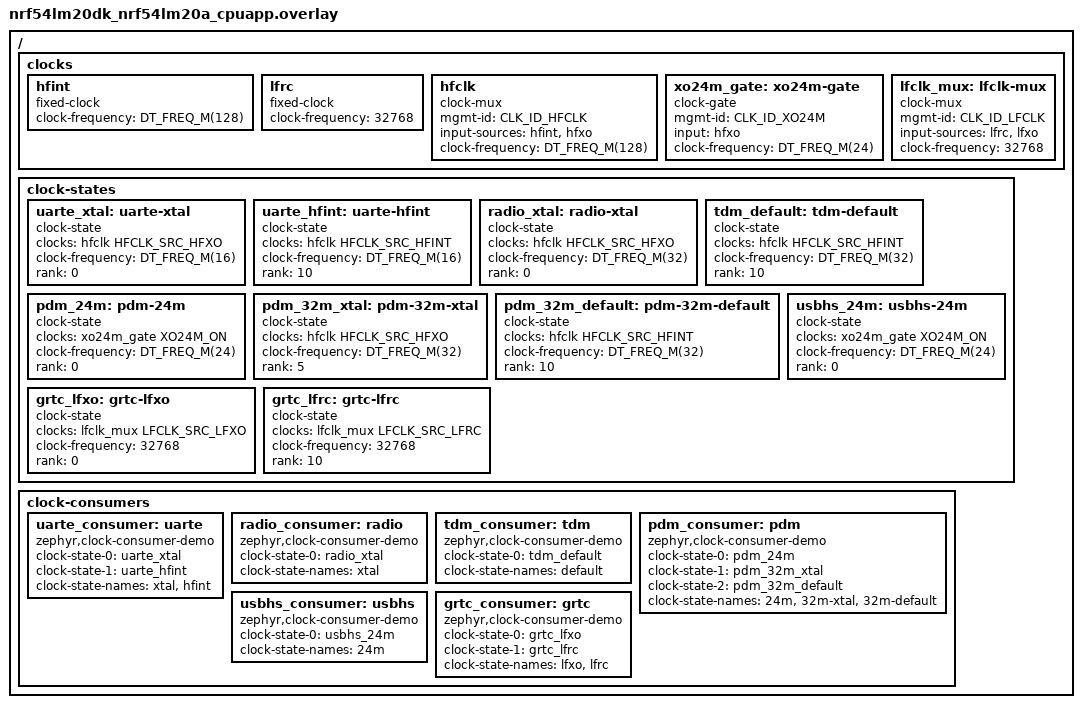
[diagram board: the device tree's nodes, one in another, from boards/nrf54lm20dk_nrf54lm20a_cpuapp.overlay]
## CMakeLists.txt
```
# Copyright (c) 2026 Nordic Semiconductor ASA
# SPDX-License-Identifier: Apache-2.0

cmake_minimum_required(VERSION 3.20.0)

find_package(Zephyr REQUIRED HINTS $ENV{ZEPHYR_BASE})
project(clock_management_hfxo)

target_sources(app PRIVATE src/main.c src/clock_mgmt.c)
target_include_directories(app PRIVATE boards)
```

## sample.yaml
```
sample:
  name: Clock-state concept demo (nRF54LM20B)
  description: >
    Models the nRF54LM20B clock tree as devicetree producers, binds peripherals
    (consumers) to them with clock-state nodes carrying a rank, and drives the
    producers at runtime through the reference-counted nrf_clock_control
    request/release API so multiple consumers can share a clock.
tests:
  sample.boards.nordic.clock_management_hfxo:
    platform_allow:
      - nrf54lm20dk/nrf54lm20a/cpuapp
    integration_platforms:
      - nrf54lm20dk/nrf54lm20a/cpuapp
    tags:
      - clock_control
      - clock_management
    harness: console
    harness_config:
      type: multi_line
      ordered: true
      regex:
        - "Clock-state concept demo"
        - "shared HFCLK arbitration"
        - "XO24M forces HFXO"
```

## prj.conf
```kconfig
CONFIG_CLOCK_CONTROL=y
CONFIG_LOG=y
```

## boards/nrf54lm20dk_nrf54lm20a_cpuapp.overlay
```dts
/*
 * Copyright (c) 2026 Nordic Semiconductor ASA
 *
 * SPDX-License-Identifier: Apache-2.0
 *
 * Models the nRF54LM20B clock tree as devicetree clock producers and binds
 * peripherals (consumers) to it via clock-state nodes. Each clock-state encodes
 * a selection in the tree (a mux input or a gate setting) plus a rank. When a
 * consumer applies a state, the clock-management layer resolves the whole path
 * from the selected node up to its source and arbitrates shared nodes by rank.
 *
 *   Sources        Muxes / gate            Outputs (pclk*)      Consumers
 *   -------        ------------            ---------------      ---------
 *   HFINT ---+
 *            +--> HFCLK (mux) --+--> PCLK32M --> RADIO, PDM, TDM
 *   HFXTAL --+                  +--> PCLK16M --> UARTE
 *      |                        +--> PCLK1M
 *      |                        +--> HCLKCORE -> CPU
 *      +--------> XO24M (gate)--+--> PCLK24M --> USBHS, PDM
 *   LFRC ----+
 *            +--> LFCLK (mux) --+--> PCLK32Ki -> GRTC
 *   LFXTAL --+   (SYNT from HFCLK)
 */

#include "clock_ids.h"

/ {
	clocks {
		/* Internal always-on sources. */
		hfint: hfint {
			compatible = "fixed-clock";
			#clock-cells = <0>;
			clock-frequency = <DT_FREQ_M(128)>;
		};

		lfrc: lfrc {
			compatible = "fixed-clock";
			#clock-cells = <0>;
			clock-frequency = <32768>;
		};

		/* HFXTAL (&hfxo) and LFXTAL (&lfxo) come from the SoC devicetree. */

		/* HFCLK: mux(HFINT, HFXTAL). Feeds PCLK32M/16M/1M and HCLKCORE. */
		hfclk: hfclk {
			compatible = "clock-mux";
			#clock-cells = <1>;
			mgmt-id = <CLK_ID_HFCLK>;
			input-sources = <&hfint &hfxo>;
			clock-frequency = <DT_FREQ_M(128)>;
		};

		/* XO24M: gate derived from HFXTAL. Feeds PCLK24M. */
		xo24m_gate: xo24m-gate {
			compatible = "clock-gate";
			#clock-cells = <1>;
			mgmt-id = <CLK_ID_XO24M>;
			input = <&hfxo>;
			clock-frequency = <DT_FREQ_M(24)>;
		};

		/* LFCLK: mux(LFRC, LFXTAL). Feeds PCLK32Ki. */
		lfclk_mux: lfclk-mux {
			compatible = "clock-mux";
			#clock-cells = <1>;
			mgmt-id = <CLK_ID_LFCLK>;
			input-sources = <&lfrc &lfxo>;
			clock-frequency = <32768>;
		};
	};

	/* Selectable configurations (like pinctrl states), grouped for clarity. */
	clock-states {
		/* UARTE on PCLK16M: prefers HFXO, tolerates HFINT. */
		uarte_xtal: uarte-xtal {
			compatible = "clock-state";
			clocks = <&hfclk HFCLK_SRC_HFXO>;
			clock-frequency = <DT_FREQ_M(16)>;
			rank = <0>;
		};
		uarte_hfint: uarte-hfint {
			compatible = "clock-state";
			clocks = <&hfclk HFCLK_SRC_HFINT>;
			clock-frequency = <DT_FREQ_M(16)>;
			rank = <10>;
		};

		/* RADIO on PCLK32M: requires HFXO. */
		radio_xtal: radio-xtal {
			compatible = "clock-state";
			clocks = <&hfclk HFCLK_SRC_HFXO>;
			clock-frequency = <DT_FREQ_M(32)>;
			rank = <0>;
		};

		/* TDM on PCLK32M: default (HFINT) is fine. */
		tdm_default: tdm-default {
			compatible = "clock-state";
			clocks = <&hfclk HFCLK_SRC_HFINT>;
			clock-frequency = <DT_FREQ_M(32)>;
			rank = <10>;
		};

		/* PDM: best on PCLK24M (XO24M), else PCLK32M xtal, else HFINT. */
		pdm_24m: pdm-24m {
			compatible = "clock-state";
			clocks = <&xo24m_gate XO24M_ON>;
			clock-frequency = <DT_FREQ_M(24)>;
			rank = <0>;
		};
		pdm_32m_xtal: pdm-32m-xtal {
			compatible = "clock-state";
			clocks = <&hfclk HFCLK_SRC_HFXO>;
			clock-frequency = <DT_FREQ_M(32)>;
			rank = <5>;
		};
		pdm_32m_default: pdm-32m-default {
			compatible = "clock-state";
			clocks = <&hfclk HFCLK_SRC_HFINT>;
			clock-frequency = <DT_FREQ_M(32)>;
			rank = <10>;
		};

		/* USBHS on PCLK24M: requires XO24M. */
		usbhs_24m: usbhs-24m {
			compatible = "clock-state";
			clocks = <&xo24m_gate XO24M_ON>;
			clock-frequency = <DT_FREQ_M(24)>;
			rank = <0>;
		};

		/* GRTC on PCLK32Ki: prefers LFXTAL, tolerates LFRC. */
		grtc_lfxo: grtc-lfxo {
			compatible = "clock-state";
			clocks = <&lfclk_mux LFCLK_SRC_LFXO>;
			clock-frequency = <32768>;
			rank = <0>;
		};
		grtc_lfrc: grtc-lfrc {
			compatible = "clock-state";
			clocks = <&lfclk_mux LFCLK_SRC_LFRC>;
			clock-frequency = <32768>;
			rank = <10>;
		};
	};

	/* Consumers: peripherals bound to clock-states. */
	clock-consumers {
		uarte_consumer: uarte {
			compatible = "zephyr,clock-consumer-demo";
			clock-state-0 = <&uarte_xtal>;
			clock-state-1 = <&uarte_hfint>;
			clock-state-names = "xtal", "hfint";
		};

		radio_consumer: radio {
			compatible = "zephyr,clock-consumer-demo";
			clock-state-0 = <&radio_xtal>;
			clock-state-names = "xtal";
		};

		tdm_consumer: tdm {
			compatible = "zephyr,clock-consumer-demo";
			clock-state-0 = <&tdm_default>;
			clock-state-names = "default";
		};

		pdm_consumer: pdm {
			compatible = "zephyr,clock-consumer-demo";
			clock-state-0 = <&pdm_24m>;
			clock-state-1 = <&pdm_32m_xtal>;
			clock-state-2 = <&pdm_32m_default>;
			clock-state-names = "24m", "32m-xtal", "32m-default";
		};

		usbhs_consumer: usbhs {
			compatible = "zephyr,clock-consumer-demo";
			clock-state-0 = <&usbhs_24m>;
			clock-state-names = "24m";
		};

		grtc_consumer: grtc {
			compatible = "zephyr,clock-consumer-demo";
			clock-state-0 = <&grtc_lfxo>;
			clock-state-1 = <&grtc_lfrc>;
			clock-state-names = "lfxo", "lfrc";
		};
	};
};
```

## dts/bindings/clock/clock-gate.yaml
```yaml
# Copyright (c) 2026 Nordic Semiconductor ASA
# SPDX-License-Identifier: Apache-2.0

description: |
  A gateable clock derived from a single input. A clock-state enables/disables
  it via a specifier cell (0 = off, non-zero = on). Enabling it implies its
  input must be running, which the clock-management layer propagates upstream.

compatible: "clock-gate"

include: [base.yaml, clock-controller.yaml]

properties:
  "#clock-cells":
    const: 1

  mgmt-id:
    type: int
    required: true
    description: Stable node id used by the clock-management layer (see clock_ids.h).

  input:
    type: phandle
    required: true
    description: The upstream clock this gate derives from.

  clock-frequency:
    type: int
    description: Output frequency (Hz).

clock-cells:
  - source
```

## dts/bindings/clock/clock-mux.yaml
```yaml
# Copyright (c) 2026 Nordic Semiconductor ASA
# SPDX-License-Identifier: Apache-2.0

description: |
  A clock multiplexer that selects its output from one of several input
  sources. A clock-state configures it via a specifier cell that selects the
  zero-based index into input-sources. The clock-management layer arbitrates
  between competing selections by rank.

compatible: "clock-mux"

include: [base.yaml, clock-controller.yaml]

properties:
  "#clock-cells":
    const: 1

  mgmt-id:
    type: int
    required: true
    description: Stable node id used by the clock-management layer (see clock_ids.h).

  input-sources:
    type: phandles
    required: true
    description: Candidate input clocks, in mux-index order.

  clock-frequency:
    type: int
    description: Nominal output frequency (Hz).

clock-cells:
  - source
```

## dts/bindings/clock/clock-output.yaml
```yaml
# Copyright (c) 2026 Nordic Semiconductor ASA
# SPDX-License-Identifier: Apache-2.0

description: |
  Software-only virtual node representing a clock signal (output) produced by a
  clock node. Clock consumers reference such outputs, and clock-state nodes that
  configure the output are defined as its children (analogous to pinctrl states).

compatible: "clock-output"

properties:
  "#clock-cells":
    type: int
    required: true
```

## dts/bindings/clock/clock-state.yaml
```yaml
# Copyright (c) 2026 Nordic Semiconductor ASA
# SPDX-License-Identifier: Apache-2.0

description: |
  A statically defined clock configuration a consumer can select, similar to a
  pinctrl state. It encodes a selection in the clock tree (which node, and which
  of its inputs/gate setting) and a rank used to arbitrate between candidate
  configurations at runtime (lower is preferred). Applying it makes the
  clock-management layer resolve the whole path from the selected node up to its
  source.

compatible: "clock-state"

properties:
  clocks:
    type: phandle-array
    required: true
    description: |
      The clock node this state configures, plus a specifier cell selecting the
      input (for a mux) or the gate setting (for a gate).

  clock-frequency:
    type: int
    required: true
    description: Frequency (Hz) produced at the consumer when this state is applied.

  rank:
    type: int
    default: 0
    description: |
      Rank used to arbitrate between candidate configurations. Lower is
      preferred (0 = best). On a shared node the best-ranked requested selection
      wins for every downstream consumer.
```

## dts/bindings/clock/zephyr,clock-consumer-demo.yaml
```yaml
# Copyright (c) 2026 Nordic Semiconductor ASA
# SPDX-License-Identifier: Apache-2.0

description: |
  Demonstration clock consumer. It binds to one or more clock-state nodes,
  exactly like a pinctrl consumer binds to pinctrl states. The binding is fully
  described in devicetree and fetched at build time by the application.

compatible: "zephyr,clock-consumer-demo"

properties:
  clock-state-0:
    type: phandle
    description: Clock state referenced by index 0 (see clock-state-names).

  clock-state-1:
    type: phandle
    description: Clock state referenced by index 1 (see clock-state-names).

  clock-state-2:
    type: phandle
    description: Clock state referenced by index 2 (see clock-state-names).

  clock-state-3:
    type: phandle
    description: Clock state referenced by index 3 (see clock-state-names).

  clock-state-names:
    type: string-array
    description: Names for the clock-state-N entries, in matching order.
```

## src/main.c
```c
/*
 * Copyright (c) 2026 Nordic Semiconductor ASA
 *
 * SPDX-License-Identifier: Apache-2.0
 */

#include <zephyr/kernel.h>
#include <zephyr/device.h>
#include <zephyr/devicetree.h>
#include <zephyr/logging/log.h>

#include "clock_mgmt.h"

LOG_MODULE_REGISTER(main, LOG_LEVEL_INF);

/* Consumers described in the board overlay (nRF54LM20B clock tree). */
CLK_CONSUMER_DEFINE(uarte, DT_NODELABEL(uarte_consumer));
CLK_CONSUMER_DEFINE(radio, DT_NODELABEL(radio_consumer));
CLK_CONSUMER_DEFINE(pdm, DT_NODELABEL(pdm_consumer));
CLK_CONSUMER_DEFINE(usbhs, DT_NODELABEL(usbhs_consumer));
CLK_CONSUMER_DEFINE(grtc, DT_NODELABEL(grtc_consumer));

static void step(const char *what)
{
	LOG_INF("%s", what);
	k_sleep(K_MSEC(800));
}

int main(void)
{
	LOG_INF("Clock-state concept demo (nRF54LM20B, tree resolution + rank)");

	clkmgmt_register(&uarte);
	clkmgmt_register(&radio);
	clkmgmt_register(&pdm);
	clkmgmt_register(&usbhs);
	clkmgmt_register(&grtc);

	while (1) {
		/*
		 * 1. UARTE tolerates HFINT and nobody needs the crystal yet, so
		 *    HFCLK resolves to HFINT and HFXO stays off.
		 */
		step("== 1. uarte applies 'hfint' (rank 10) ==");
		clkmgmt_apply(&uarte, "hfint");
		clkmgmt_report("uarte hfint");

		/*
		 * 2. RADIO needs the crystal (rank 0). Arbitration on the shared
		 *    HFCLK node makes HFXO win - and UARTE, though it asked for
		 *    HFINT, is upgraded to HFXO too.
		 */
		step("== 2. radio applies 'xtal' (rank 0) - shared HFCLK arbitration ==");
		clkmgmt_apply(&radio, "xtal");
		clkmgmt_report("uarte hfint + radio xtal");

		step("== 3. radio releases - HFCLK falls back to HFINT ==");
		clkmgmt_release(&radio);
		clkmgmt_report("uarte hfint only");

		/*
		 * 4. USBHS needs XO24M, which requires HFXO. HFCLK opportunistically
		 *    upgrades to HFXO, so UARTE rides the crystal again "for free".
		 */
		step("== 4. usbhs applies '24m' - XO24M forces HFXO, HFCLK upgrades ==");
		clkmgmt_apply(&usbhs, "24m");
		clkmgmt_report("uarte hfint + usbhs 24m");

		/* 5. PDM arbitrates its own three candidate states -> best rank (24m). */
		step("== 5. pdm applies best-ranked state (rank arbitration) ==");
		clkmgmt_apply(&pdm, pdm.states[0].name);
		clkmgmt_report("+ pdm 24m");

		/* 6. GRTC brings up the LF domain independently. */
		step("== 6. grtc applies 'lfxo' - independent LF domain ==");
		clkmgmt_apply(&grtc, "lfxo");
		clkmgmt_report("+ grtc lfxo");

		/* 7. Tear everything down; HFXO/XO24M/LFCLK all drop. */
		step("== 7. release all ==");
		clkmgmt_release(&uarte);
		clkmgmt_release(&usbhs);
		clkmgmt_release(&pdm);
		clkmgmt_release(&grtc);
		clkmgmt_report("idle");

		k_sleep(K_SECONDS(3));
	}

	return 0;
}
```

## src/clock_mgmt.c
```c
/*
 * Copyright (c) 2026 Nordic Semiconductor ASA
 *
 * SPDX-License-Identifier: Apache-2.0
 */

#include <string.h>

#include <zephyr/kernel.h>
#include <zephyr/device.h>
#include <zephyr/devicetree.h>
#include <zephyr/drivers/clock_control.h>
#include <zephyr/drivers/clock_control/nrf_clock_control.h>
#include <zephyr/logging/log.h>

#include "clock_ids.h"
#include "clock_mgmt.h"

LOG_MODULE_REGISTER(clkmgmt, LOG_LEVEL_INF);

#define CLK_REQUEST_TIMEOUT K_MSEC(500)
#define MAX_CONSUMERS       16

/*
 * Leaf producers that are actually driven at runtime. The rest of the tree
 * (muxes, gate, derived clocks) is resolved in software: on nRF54LM20B,
 * "HFCLK = HFXTAL" effectively means "HFXO is requested", so the mux source is
 * inferred rather than programmed via a dedicated register.
 */
static const struct device *const hfxo_dev = DEVICE_DT_GET(DT_NODELABEL(xo));
static const struct device *const xo24m_dev = DEVICE_DT_GET(DT_NODELABEL(xo24m));
static const struct device *const lfclk_dev = DEVICE_DT_GET(DT_NODELABEL(lfclk));

static struct clk_consumer *consumers[MAX_CONSUMERS];
static size_t n_consumers;

/* Current leaf hold state, so re-resolution only issues the deltas. */
static bool hfxo_held;
static bool xo24m_held;
static bool lfclk_held;

/* Result of the most recent resolution. */
static struct {
	uint8_t hfclk_src; /* HFCLK_SRC_* */
	uint8_t lfclk_src; /* LFCLK_SRC_* */
	bool xo24m_on;
	bool lfclk_on;
	bool hfxo_on;
} resolved;

void clkmgmt_register(struct clk_consumer *consumer)
{
	__ASSERT_NO_MSG(n_consumers < MAX_CONSUMERS);
	consumers[n_consumers++] = consumer;
}

static void leaf_set(const struct device *dev, bool *held, bool want)
{
	if (want && !*held) {
		int err = nrf_clock_control_request_sync(dev, NULL, CLK_REQUEST_TIMEOUT);

		if (err < 0) {
			LOG_ERR("request '%s' failed (%d)", dev->name, err);
			return;
		}
		*held = true;
	} else if (!want && *held) {
		(void)nrf_clock_control_release(dev, NULL);
		*held = false;
	}
}

/*
 * The heart of the layer: recompute the whole tree from every consumer's held
 * state, arbitrate shared nodes by rank, apply the opportunistic-HFXO rule, and
 * drive the leaf producers to match.
 */
static void clkmgmt_resolve(void)
{
	bool xo24m_on = false;
	bool lfclk_on = false;
	bool hfclk_requested = false;
	uint32_t hfclk_best_rank = UINT32_MAX;
	uint8_t hfclk_src = HFCLK_SRC_HFINT;
	uint32_t lfclk_best_rank = UINT32_MAX;
	uint8_t lfclk_src = LFCLK_SRC_LFRC;

	for (size_t i = 0; i < n_consumers; i++) {
		const struct clk_setting *s = consumers[i]->active;

		if (s == NULL) {
			continue;
		}

		switch (s->node_id) {
		case CLK_ID_HFCLK:
			hfclk_requested = true;
			if (s->rank < hfclk_best_rank) {
				hfclk_best_rank = s->rank;
				hfclk_src = s->source;
			}
			break;
		case CLK_ID_XO24M:
			xo24m_on = xo24m_on || (s->source == XO24M_ON);
			break;
		case CLK_ID_LFCLK:
			lfclk_on = true;
			if (s->rank < lfclk_best_rank) {
				lfclk_best_rank = s->rank;
				lfclk_src = s->source;
			}
			break;
		default:
			break;
		}
	}

	/*
	 * HFXO must run if the HFCLK mux arbitration picked it, or if XO24M is in
	 * use (XO24M is derived from HFXTAL).
	 */
	bool hfxo_on = (hfclk_requested && hfclk_src == HFCLK_SRC_HFXO) || xo24m_on;

	/*
	 * Opportunistic upgrade: if HFXO is running for any reason, HFCLK sources
	 * from it - so even consumers that only asked for HFINT get the crystal
	 * "for free".
	 */
	resolved.hfclk_src = hfxo_on ? HFCLK_SRC_HFXO : HFCLK_SRC_HFINT;
	resolved.lfclk_src = lfclk_src;
	resolved.xo24m_on = xo24m_on;
	resolved.lfclk_on = lfclk_on;
	resolved.hfxo_on = hfxo_on;

	/* Drive the real producers to match the resolved tree. */
	leaf_set(hfxo_dev, &hfxo_held, hfxo_on);
	leaf_set(xo24m_dev, &xo24m_held, xo24m_on);
	leaf_set(lfclk_dev, &lfclk_held, lfclk_on);
}

int clkmgmt_apply(struct clk_consumer *consumer, const char *state_name)
{
	for (size_t i = 0; i < consumer->n_states; i++) {
		if (strcmp(consumer->states[i].name, state_name) == 0) {
			consumer->active = &consumer->states[i];
			clkmgmt_resolve();
			return 0;
		}
	}

	LOG_ERR("consumer '%s' has no state '%s'", consumer->name, state_name);
	return -ENOENT;
}

int clkmgmt_release(struct clk_consumer *consumer)
{
	consumer->active = NULL;
	clkmgmt_resolve();
	return 0;
}

/* Effective source seen by a consumer, after tree resolution. */
static const char *consumer_effective(const struct clk_consumer *consumer)
{
	const struct clk_setting *s = consumer->active;

	if (s == NULL) {
		return "-";
	}

	switch (s->node_id) {
	case CLK_ID_HFCLK:
		return (resolved.hfclk_src == HFCLK_SRC_HFXO) ? "HFXO" : "HFINT";
	case CLK_ID_XO24M:
		return "HFXO(24M)";
	case CLK_ID_LFCLK:
		return (resolved.lfclk_src == LFCLK_SRC_LFXO) ? "LFXO" : "LFRC";
	default:
		return "?";
	}
}

static const char *onoff(bool on)
{
	return on ? "on" : "off";
}

void clkmgmt_report(const char *ctx)
{
	LOG_INF("  [%s]", ctx);
	LOG_INF("    tree: HFXO=%s XO24M=%s LFCLK=%s | HFCLK src=%s | LFCLK src=%s",
		onoff(clock_control_get_status(hfxo_dev, NULL) == CLOCK_CONTROL_STATUS_ON),
		onoff(resolved.xo24m_on), onoff(resolved.lfclk_on),
		(resolved.hfclk_src == HFCLK_SRC_HFXO) ? "HFXO" : "HFINT",
		(resolved.lfclk_src == LFCLK_SRC_LFXO) ? "LFXO" : "LFRC");

	for (size_t i = 0; i < n_consumers; i++) {
		const struct clk_consumer *c = consumers[i];

		if (c->active == NULL) {
			continue;
		}

		LOG_INF("    %-6s wants %-11s -> effective %-9s (%u Hz)", c->name, c->active->name,
			consumer_effective(c), c->active->freq);
	}
}
```

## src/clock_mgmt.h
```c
/*
 * Copyright (c) 2026 Nordic Semiconductor ASA
 *
 * SPDX-License-Identifier: Apache-2.0
 *
 * Sample-local clock-management layer. It sits on top of the producer drivers:
 * consumers apply named clock-states (fetched from devicetree at build time),
 * and this layer resolves the whole clock tree, arbitrates shared nodes by rank,
 * applies the opportunistic-HFXO rule, and enables/disables the leaf producers
 * (HFXO / XO24M / LFCLK) accordingly.
 *
 * It is a stand-in for a future clock-management framework.
 */

#ifndef CLOCK_MGMT_H_
#define CLOCK_MGMT_H_

#include <stddef.h>
#include <stdint.h>

#include <zephyr/devicetree.h>
#include <zephyr/sys/util.h>

/**
 * @brief One selectable configuration, resolved from a "clock-state" node.
 *
 * @param name     Human-readable name (from the consumer's clock-state-names).
 * @param node_id  Tree node this state configures (CLK_ID_*, from its mgmt-id).
 * @param source   Selector cell: mux input index or gate on/off.
 * @param rank     Arbitration rank (lower is preferred).
 * @param freq     Peripheral frequency (Hz) this state yields.
 */
struct clk_setting {
	const char *name;
	uint8_t node_id;
	uint8_t source;
	uint32_t rank;
	uint32_t freq;
};

/** @brief A clock consumer and the state it currently holds (if any). */
struct clk_consumer {
	const char *name;
	const struct clk_setting *states;
	size_t n_states;
	const struct clk_setting *active; /* NULL when released */
};

/* --- Build-time helpers to turn a consumer DT node into a states table --- */

#define _CLK_STATE_NODE(consumer, idx) DT_PHANDLE(consumer, clock_state_##idx)
#define _CLK_STATE_TARGET(state)       DT_PHANDLE_BY_IDX(state, clocks, 0)

#define _CLK_SETTING(consumer, idx)                                                                \
	COND_CODE_1(DT_NODE_HAS_PROP(consumer, clock_state_##idx),                                  \
		    ({                                                                             \
			    .name = DT_PROP_BY_IDX(consumer, clock_state_names, idx),               \
			    .node_id =                                                              \
				    DT_PROP(_CLK_STATE_TARGET(_CLK_STATE_NODE(consumer, idx)),      \
					    mgmt_id),                                              \
			    .source = DT_PHA_BY_IDX(_CLK_STATE_NODE(consumer, idx), clocks, 0,      \
						    source),                                           \
			    .rank = DT_PROP(_CLK_STATE_NODE(consumer, idx), rank),                  \
			    .freq = DT_PROP(_CLK_STATE_NODE(consumer, idx), clock_frequency),       \
		    },),                                                                           \
		    ())

/** @brief Build a `struct clk_setting[]` initializer for a consumer's states. */
#define CLK_CONSUMER_STATES(consumer)                                                              \
	{                                                                                          \
		_CLK_SETTING(consumer, 0)                                                           \
		_CLK_SETTING(consumer, 1)                                                           \
		_CLK_SETTING(consumer, 2)                                                           \
		_CLK_SETTING(consumer, 3)                                                           \
	}

/** @brief Define and initialize a consumer object from its DT node. */
#define CLK_CONSUMER_DEFINE(var, node)                                                             \
	static const struct clk_setting var##_states[] = CLK_CONSUMER_STATES(node);                \
	static struct clk_consumer var = {                                                         \
		.name = DT_NODE_FULL_NAME(node),                                                    \
		.states = var##_states,                                                             \
		.n_states = ARRAY_SIZE(var##_states),                                               \
		.active = NULL,                                                                     \
	}

/* --- Runtime API --- */

/** @brief Register a consumer with the layer (before applying states). */
void clkmgmt_register(struct clk_consumer *consumer);

/**
 * @brief Apply a named state for @p consumer, then re-resolve the whole tree.
 *
 * @retval 0 on success, -ENOENT if the state name is unknown, or a negative
 *         errno propagated from a producer request.
 */
int clkmgmt_apply(struct clk_consumer *consumer, const char *state_name);

/** @brief Release @p consumer's state, then re-resolve the whole tree. */
int clkmgmt_release(struct clk_consumer *consumer);

/** @brief Log the resolved tree state and each active consumer's effective clock. */
void clkmgmt_report(const char *ctx);

#endif /* CLOCK_MGMT_H_ */
```

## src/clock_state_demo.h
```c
/*
 * Copyright (c) 2026 Nordic Semiconductor ASA
 *
 * SPDX-License-Identifier: Apache-2.0
 *
 * Minimal, sample-local "abstracted interface" that stands in for a future
 * clock-management framework. It turns the devicetree binding between a clock
 * consumer and its clock producer(s) into a build-time table, arbitrates
 * between candidate states by rank, and applies the selected state by
 * requesting/releasing the producer through the Nordic clock_control request
 * API. Using request/release (instead of on/off) means several consumers can
 * share the same producer: it is reference counted and only stops once the last
 * consumer releases it.
 */

#ifndef CLOCK_STATE_DEMO_H_
#define CLOCK_STATE_DEMO_H_

#include <stddef.h>
#include <stdint.h>
#include <string.h>

#include <zephyr/device.h>
#include <zephyr/devicetree.h>
#include <zephyr/kernel.h>
#include <zephyr/drivers/clock_control.h>
#include <zephyr/drivers/clock_control/nrf_clock_control.h>
#include <zephyr/sys/util.h>

/** Timeout used for the synchronous clock request. */
#define CLOCK_STATE_REQUEST_TIMEOUT K_MSEC(500)

/**
 * @brief One resolved clock state fetched from devicetree.
 *
 * All fields are populated at build time from a "clock-state" node:
 *  - @ref producer is resolved from the state's `clocks` phandle. It may be
 *    NULL, which models a state that needs no runtime action (e.g. an
 *    always-on internal oscillator such as HFINT / LFRC).
 *  - @ref rank / @ref frequency come from the `rank` / `clock-frequency` props.
 */
struct clock_state {
	const char *name;
	const struct device *producer;
	uint32_t rank;
	uint32_t frequency;
};

/** Rank constraint that accepts any state (no upper bound). */
#define CLOCK_STATE_DEMO_MAX_RANK UINT32_MAX

/*
 * Resolve a clock-state node to its (first) producer device, or NULL when the
 * state has no `clocks` phandle (nothing to request at runtime).
 */
#define CLOCK_STATE_PRODUCER(state_node)                                                           \
	COND_CODE_1(DT_NODE_HAS_PROP(state_node, clocks),                                           \
		    (DEVICE_DT_GET(DT_PHANDLE_BY_IDX(state_node, clocks, 0))), (NULL))

/* Build one struct clock_state initializer for consumer's clock-state-<idx>. */
#define CLOCK_STATE_DEMO_ENTRY(consumer, idx)                                                      \
	COND_CODE_1(DT_NODE_HAS_PROP(consumer, clock_state_##idx),                                  \
		    ({                                                                             \
			    .name = DT_PROP_BY_IDX(consumer, clock_state_names, idx),               \
			    .producer =                                                             \
				    CLOCK_STATE_PRODUCER(DT_PHANDLE(consumer, clock_state_##idx)),  \
			    .rank = DT_PROP(DT_PHANDLE(consumer, clock_state_##idx), rank),         \
			    .frequency = DT_PROP(DT_PHANDLE(consumer, clock_state_##idx),           \
						 clock_frequency),                                     \
		    },),                                                                           \
		    ())

/**
 * @brief Build a `struct clock_state[]` initializer for all states of a consumer.
 *
 * Supports up to four states (clock-state-0..3), mirroring the sample binding.
 */
#define CLOCK_STATE_DEMO_STATES(consumer)                                                          \
	{                                                                                          \
		CLOCK_STATE_DEMO_ENTRY(consumer, 0)                                                 \
		CLOCK_STATE_DEMO_ENTRY(consumer, 1)                                                 \
		CLOCK_STATE_DEMO_ENTRY(consumer, 2)                                                 \
		CLOCK_STATE_DEMO_ENTRY(consumer, 3)                                                 \
	}

/**
 * @brief Apply a clock state: request its producer (reference counted, blocking).
 *
 * States with no producer (NULL) are a no-op success: they represent a default
 * internal source that is always available.
 */
static inline int clock_state_apply(const struct clock_state *state)
{
	if (state->producer == NULL) {
		return 0;
	}

	return nrf_clock_control_request_sync(state->producer, NULL, CLOCK_STATE_REQUEST_TIMEOUT);
}

/**
 * @brief Release a clock state: drop this consumer's request on the producer.
 *
 * The producer only actually stops once every consumer that requested it has
 * released it.
 */
static inline int clock_state_release(const struct clock_state *state)
{
	if (state->producer == NULL) {
		return 0;
	}

	return nrf_clock_control_release(state->producer, NULL);
}

/**
 * @brief Select the best (lowest-rank) state not exceeding @p max_rank.
 *
 * Rank arbitration: lower is preferred (0 = best). The @p max_rank constraint
 * is "sticky" - states ranked above it are never eligible.
 *
 * @return Pointer to the selected state, or NULL if none is eligible.
 */
static inline const struct clock_state *
clock_state_select_by_rank(const struct clock_state *states, size_t count, uint32_t max_rank)
{
	const struct clock_state *best = NULL;

	for (size_t i = 0; i < count; i++) {
		if (states[i].rank > max_rank) {
			continue;
		}

		if ((best == NULL) || (states[i].rank < best->rank)) {
			best = &states[i];
		}
	}

	return best;
}

/** @brief Find a state by name within a table, or NULL if not present. */
static inline const struct clock_state *
clock_state_find(const struct clock_state *states, size_t count, const char *name)
{
	for (size_t i = 0; i < count; i++) {
		if (strcmp(states[i].name, name) == 0) {
			return &states[i];
		}
	}

	return NULL;
}

#endif /* CLOCK_STATE_DEMO_H_ */
```
